# PIC18F16Q20 register map
Vendor: Microchip
Registers are 8-bit, read-write, reset 0x0 unless marked. A register's access mark holds for its fields unless they carry their own. Addresses are absolute, and some are shared; only a register's first bit layout is shown; [hi:lo] are bit positions; {n}, {i} and the like mark numbered series.

## pmd
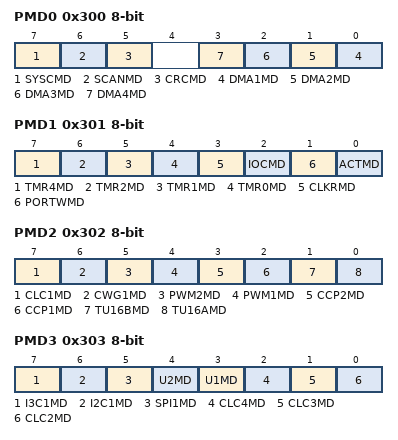
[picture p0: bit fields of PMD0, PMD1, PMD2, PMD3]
0x300 PMD0
  [7] SYSCMD, [6] SCANMD, [5] CRCMD, [n-1] DMA{n}MD (n=1..4)
0x301 PMD1
  [7] TMR4MD, [6] TMR2MD, [5] TMR1MD, [4] TMR0MD, [3] CLKRMD, [2] IOCMD, [1] PORTWMD, [0] ACTMD
0x302 PMD2
  [7] CLC1MD, [6] CWG1MD, [5] PWM2MD, [4] PWM1MD, [3] CCP2MD, [2] CCP1MD, [1] TU16BMD, [0] TU16AMD
0x303 PMD3
  [7] I3C1MD, [6] I2C1MD, [5] SPI1MD, [4] U2MD, [3] U1MD, [2] CLC4MD, [1] CLC3MD, [0] CLC2MD
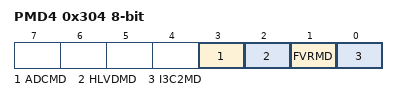
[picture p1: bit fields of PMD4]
0x304 PMD4 reset not defined — (power-on value ----0x00)
  [3] ADCMD, [2] HLVDMD, [1] FVRMD, [0] I3C2MD

## DOS_xxxxx_pps_mid_v2_output_8bit
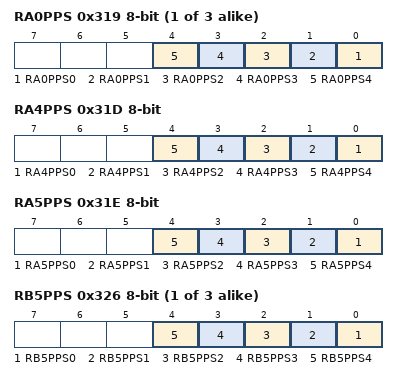
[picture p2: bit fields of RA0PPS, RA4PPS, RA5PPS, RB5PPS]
{0x319+i} RA{i}PPS (i=0..2)
  [n] RA{i}PPS{n} (n=0..4)
0x31D RA4PPS
  [n] RA4PPS{n} (n=0..4)
0x31E RA5PPS
  [n] RA5PPS{n} (n=0..4)
{0x321+i} RB{i}PPS (i=5..7)
  [n] RB{i}PPS{n} (n=0..4)
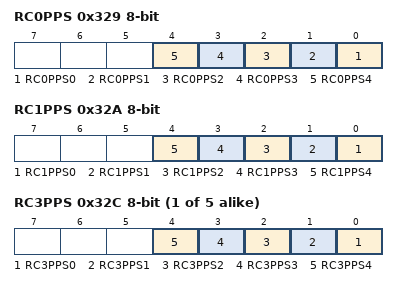
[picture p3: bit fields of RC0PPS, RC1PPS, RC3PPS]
0x329 RC0PPS
  [n] RC0PPS{n} (n=0..4)
0x32A RC1PPS
  [n] RC1PPS{n} (n=0..4)
{0x329+i} RC{i}PPS (i=3..7)
  [n] RC{i}PPS{n} (n=0..4)

## pps_mid
0x352 INT0PPS reset 0x2
  [4:0] INT0PPS
0x353 INT1PPS reset 0x4
  [4:0] INT1PPS
0x354 INT2PPS reset 0x5
  [4:0] INT2PPS
0x355 T0CKIPPS reset 0x2
  [4:0] T0CKIPPS
0x356 T1CKIPPS reset 0x5
  [4:0] T1CKIPPS
0x357 T1GPPS reset 0x4
  [4:0] T1GPPS
0x360 T2INPPS reset 0x5
  [4:0] T2INPPS
0x361 T4INPPS reset 0x11
  [4:0] T4INPPS
0x365 TUIN0PPS reset 0x1
  [4:0] TUIN0PPS
0x366 TUIN1PPS reset 0x10
  [4:0] TUIN1PPS
0x369 CCP1PPS reset 0x15
  [4:0] CCP1PPS
0x36A CCP2PPS reset 0x13
  [4:0] CCP2PPS
0x384 PWMIN0PPS reset 0x15
  [4:0] PWMIN0PPS
0x385 PWMIN1PPS reset 0x13
  [4:0] PWMIN1PPS
0x386 PWM1ERSPPS reset 0x5
  [4:0] PWM1ERSPPS
0x387 PWM2ERSPPS reset 0x11
  [4:0] PWM2ERSPPS
0x399 CWG1PPS reset 0x2
  [4:0] CWG1INPPS
0x39D CLCIN0PPS reset 0x2
  [4:0] CLCIN0PPS
0x39E CLCIN1PPS reset 0x13
  [4:0] CLCIN1PPS
0x39F CLCIN2PPS reset 0xE
  [4:0] CLCIN2PPS
0x3A0 CLCIN3PPS reset 0xD
  [4:0] CLCIN3PPS
0x3A1 U1CTSPPS reset 0xF
  [4:0] U1CTSPPS
0x3A2 U1RXPPS reset 0xD
  [4:0] U1RXPPS
0x3A3 U2CTSPPS reset 0x10
  [4:0] U2CTSPPS
0x3A4 U2RXPPS reset 0x11
  [4:0] U2RXPPS
0x3A7 SPI1SCKPPS reset 0xE
  [4:0] SPI1SCKPPS
0x3A8 SPI1SDIPPS reset 0xD
  [4:0] SPI1SDIPPS
0x3A9 SPI1SSPPS reset 0x16
  [4:0] SPI1SSPPS
0x3AD I2C1SCLPPS reset 0xE
  [4:0] I2C1SCLPPS
0x3AE I2C1SDAPPS reset 0xD
  [4:0] I2C1SDAPPS
0x3B1 ADACTPPS reset 0x13
  [4:0] ADACTPPS

## DOS_xxxxx_port_control
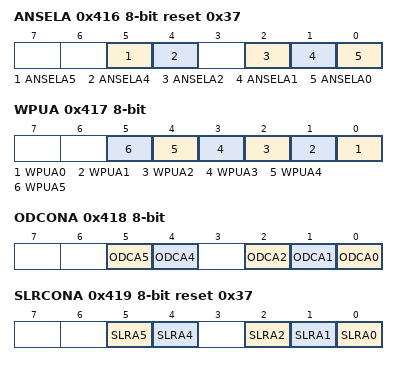
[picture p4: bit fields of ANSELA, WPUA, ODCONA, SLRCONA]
0x416 ANSELA reset 0x37
  [5] ANSELA5, [4] ANSELA4, [2] ANSELA2, [1] ANSELA1, [0] ANSELA0
0x417 WPUA
  [n] WPUA{n} (n=0..5)
0x418 ODCONA
  [5] ODCA5, [4] ODCA4, [2] ODCA2, [1] ODCA1, [0] ODCA0
0x419 SLRCONA reset 0x37
  [5] SLRA5, [4] SLRA4, [2] SLRA2, [1] SLRA1, [0] SLRA0
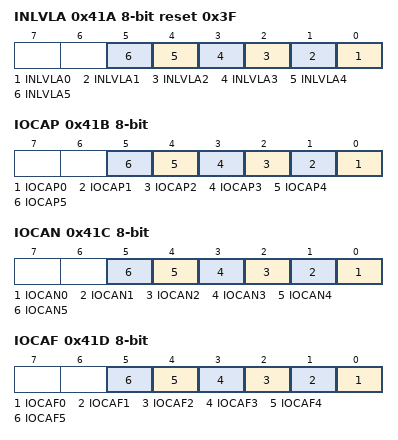
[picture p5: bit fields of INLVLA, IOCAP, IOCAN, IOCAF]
0x41A INLVLA reset 0x3F
  [n] INLVLA{n} (n=0..5)
0x41B IOCAP
  [n] IOCAP{n} (n=0..5)
0x41C IOCAN
  [n] IOCAN{n} (n=0..5)
0x41D IOCAF
  [n] IOCAF{n} (n=0..5)
0x420 ANSELB reset 0x80
  [7] ANSELB7
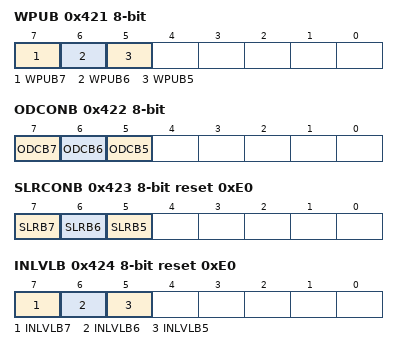
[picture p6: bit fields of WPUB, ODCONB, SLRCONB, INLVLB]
0x421 WPUB
  [7] WPUB7, [6] WPUB6, [5] WPUB5
0x422 ODCONB
  [7] ODCB7, [6] ODCB6, [5] ODCB5
0x423 SLRCONB reset 0xE0
  [7] SLRB7, [6] SLRB6, [5] SLRB5
0x424 INLVLB reset 0xE0
  [7] INLVLB7, [6] INLVLB6, [5] INLVLB5
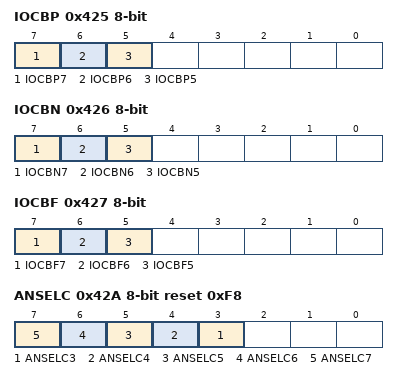
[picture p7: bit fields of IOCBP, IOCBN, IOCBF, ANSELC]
0x425 IOCBP
  [7] IOCBP7, [6] IOCBP6, [5] IOCBP5
0x426 IOCBN
  [7] IOCBN7, [6] IOCBN6, [5] IOCBN5
0x427 IOCBF
  [7] IOCBF7, [6] IOCBF6, [5] IOCBF5
0x42A ANSELC reset 0xF8
  [n] ANSELC{n} (n=3..7)
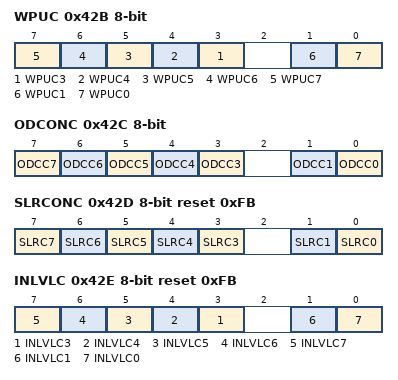
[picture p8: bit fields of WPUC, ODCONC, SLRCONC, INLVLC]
0x42B WPUC
  [n] WPUC{n} (n=3..7), [1] WPUC1, [0] WPUC0
0x42C ODCONC
  [n] ODCC{n} (n=3..7), [1] ODCC1, [0] ODCC0
0x42D SLRCONC reset 0xFB
  [n] SLRC{n} (n=3..7), [1] SLRC1, [0] SLRC0
0x42E INLVLC reset 0xFB
  [n] INLVLC{n} (n=3..7), [1] INLVLC1, [0] INLVLC0
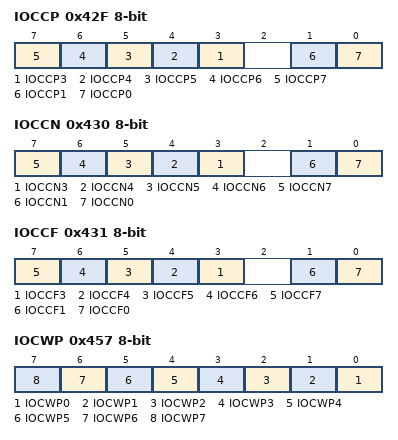
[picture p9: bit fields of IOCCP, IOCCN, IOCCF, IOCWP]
0x42F IOCCP
  [n] IOCCP{n} (n=3..7), [1] IOCCP1, [0] IOCCP0
0x430 IOCCN
  [n] IOCCN{n} (n=3..7), [1] IOCCN1, [0] IOCCN0
0x431 IOCCF
  [n] IOCCF{n} (n=3..7), [1] IOCCF1, [0] IOCCF0
0x457 IOCWP
  [n] IOCWP{n} (n=0..7)
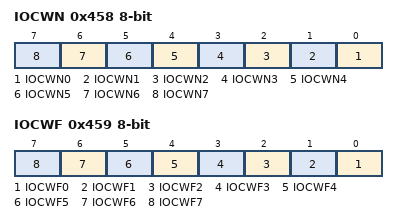
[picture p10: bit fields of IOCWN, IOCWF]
0x458 IOCWN
  [n] IOCWN{n} (n=0..7)
0x459 IOCWF
  [n] IOCWF{n} (n=0..7)
